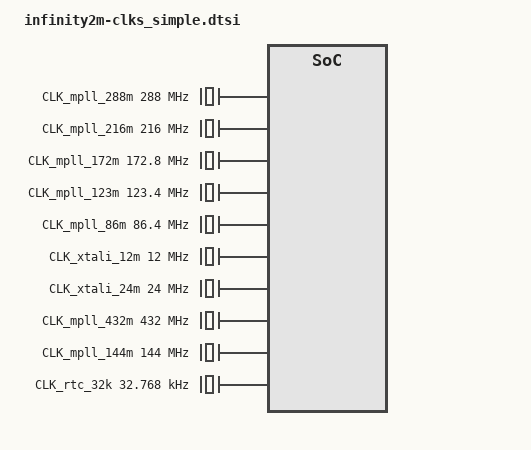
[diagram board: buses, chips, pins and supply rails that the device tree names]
/*
* infinity2m-clks_simple.dtsi- Sigmastar
*
* Copyright (c) [2019~2020] SigmaStar Technology.
*
*
* This software is licensed under the terms of the GNU General Public
* License version 2, as published by the Free Software Foundation, and
* may be copied, distributed, and modified under those terms.
*
* This program is distributed in the hope that it will be useful,
* but WITHOUT ANY WARRANTY; without even the implied warranty of
* MERCHANTABILITY or FITNESS FOR A PARTICULAR PURPOSE.  See the
* GNU General Public License version 2 for more details.
*
*/
/* generated manually for fast booting */

CLK_VOID: CLK_VOID {
    #clock-cells = <0>;
    compatible = "fixed-clock";
    clock-frequency = <1>;
};
 
CLK_upll_384m: CLK_upll_384m {
    #clock-cells = <0>;
    compatible = "fixed-factor-clock";
    clocks = <&CLK_upll>;
    clock-div = <5>;
    clock-mult = <4>;
};
 
CLK_upll_320m: CLK_upll_320m {
    #clock-cells = <0>;
    compatible = "fixed-factor-clock";
    clocks = <&CLK_upll>;
    clock-div = <3>;
    clock-mult = <2>;
};
 
CLK_mpll_288m: CLK_mpll_288m {
    #clock-cells = <0>;
    compatible = "fixed-clock";
    clock-frequency = <288000000>;
};
 
CLK_utmi_240m: CLK_utmi_240m {
    #clock-cells = <0>;
    compatible = "fixed-factor-clock";
    clocks = <&CLK_utmi>;
    clock-div = <2>;
    clock-mult = <1>;
};
 
CLK_mpll_216m: CLK_mpll_216m {
    #clock-cells = <0>;
    compatible = "fixed-clock";
    clock-frequency = <216000000>;
};
 
CLK_utmi_192m: CLK_utmi_192m {
    #clock-cells = <0>;
    compatible = "fixed-factor-clock";
    clocks = <&CLK_utmi>;
    clock-div = <5>;
    clock-mult = <2>;
};
 
CLK_mpll_172m: CLK_mpll_172m {
    #clock-cells = <0>;
    compatible = "fixed-clock";
    clock-frequency = <172800000>;
};
 
CLK_utmi_160m: CLK_utmi_160m {
    #clock-cells = <0>;
    compatible = "fixed-factor-clock";
    clocks = <&CLK_utmi>;
    clock-div = <3>;
    clock-mult = <1>;
};
 
CLK_mpll_123m: CLK_mpll_123m {
    #clock-cells = <0>;
    compatible = "fixed-clock";
    clock-frequency = <123400000>;
};
 
CLK_mpll_86m: CLK_mpll_86m {
    #clock-cells = <0>;
    compatible = "fixed-clock";
    clock-frequency = <86400000>;
};
 
CLK_mpll_288m_div2: CLK_mpll_288m_div2 {
    #clock-cells = <0>;
    compatible = "fixed-factor-clock";
    clocks = <&CLK_mpll_288m>;
    clock-div = <2>;
    clock-mult = <1>;
};
 
CLK_mpll_288m_div4: CLK_mpll_288m_div4 {
    #clock-cells = <0>;
    compatible = "fixed-factor-clock";
    clocks = <&CLK_mpll_288m>;
    clock-div = <4>;
    clock-mult = <1>;
};
 
CLK_mpll_288m_div8: CLK_mpll_288m_div8 {
    #clock-cells = <0>;
    compatible = "fixed-factor-clock";
    clocks = <&CLK_mpll_288m>;
    clock-div = <8>;
    clock-mult = <1>;
};
CLK_mpll_216m_div2: CLK_mpll_216m_div2 {
    #clock-cells = <0>;
    compatible = "fixed-factor-clock";
    clocks = <&CLK_mpll_216m>;
    clock-div = <2>;
    clock-mult = <1>;
};
 
CLK_mpll_216m_div4: CLK_mpll_216m_div4 {
    #clock-cells = <0>;
    compatible = "fixed-factor-clock";
    clocks = <&CLK_mpll_216m>;
    clock-div = <4>;
    clock-mult = <1>;
};
 
CLK_mpll_216m_div8: CLK_mpll_216m_div8 {
    #clock-cells = <0>;
    compatible = "fixed-factor-clock";
    clocks = <&CLK_mpll_216m>;
    clock-div = <8>;
    clock-mult = <1>;
};
CLK_mpll_86m_div2: CLK_mpll_86m_div2 {
    #clock-cells = <0>;
    compatible = "fixed-factor-clock";
    clocks = <&CLK_mpll_86m>;
    clock-div = <2>;
    clock-mult = <1>;
};
CLK_utmi_192m_div4: CLK_utmi_192m_div4 {
    #clock-cells = <0>;
    compatible = "fixed-factor-clock";
    clocks = <&CLK_utmi_192m>;
    clock-div = <4>;
    clock-mult = <1>;
};
 
CLK_utmi_160m_div4: CLK_utmi_160m_div4 {
    #clock-cells = <0>;
    compatible = "fixed-factor-clock";
    clocks = <&CLK_utmi_160m>;
    clock-div = <4>;
    clock-mult = <1>;
};
 
CLK_utmi_160m_div5: CLK_utmi_160m_div5 {
    #clock-cells = <0>;
    compatible = "fixed-factor-clock";
    clocks = <&CLK_utmi_160m>;
    clock-div = <5>;
    clock-mult = <1>;
};
 
CLK_utmi_160m_div8: CLK_utmi_160m_div8 {
    #clock-cells = <0>;
    compatible = "fixed-factor-clock";
    clocks = <&CLK_utmi_160m>;
    clock-div = <8>;
    clock-mult = <1>;
};
 
CLK_xtali_12m: CLK_xtali_12m {
    #clock-cells = <0>;
    compatible = "fixed-clock";
    clock-frequency = <12000000>;
};
 
CLK_xtali_12m_div8: CLK_xtali_12m_div8 {
    #clock-cells = <0>;
    compatible = "fixed-factor-clock";
    clocks = <&CLK_xtali_12m>;
    clock-div = <8>;
    clock-mult = <1>;
};
 
CLK_xtali_12m_div16: CLK_xtali_12m_div16 {
    #clock-cells = <0>;
    compatible = "fixed-factor-clock";
    clocks = <&CLK_xtali_12m>;
    clock-div = <16>;
    clock-mult = <1>;
};
 
CLK_xtali_12m_div40: CLK_xtali_12m_div40 {
    #clock-cells = <0>;
    compatible = "fixed-factor-clock";
    clocks = <&CLK_xtali_12m>;
    clock-div = <40>;
    clock-mult = <1>;
};
CLK_xtali_24m: CLK_xtali_24m {
    #clock-cells = <0>;
    compatible = "fixed-clock";
    clock-frequency = <24000000>;
};
CLK_miu_p: CLK_miu_p {
    #clock-cells = <0>;
    compatible = "fixed-factor-clock";
    clocks = <&CLK_miu>;
    clock-div = <1>;
    clock-mult = <1>;
};
 
CLK_mspi0_p: CLK_mspi0_p {
    #clock-cells = <0>;
    compatible = "fixed-factor-clock";
    clocks = <&CLK_mspi0>;
    clock-div = <1>;
    clock-mult = <1>;
};
 
CLK_mspi1_p: CLK_mspi1_p {
    #clock-cells = <0>;
    compatible = "fixed-factor-clock";
    clocks = <&CLK_mspi1>;
    clock-div = <1>;
    clock-mult = <1>;
};
 
CLK_miu_sc_gp_p: CLK_miu_sc_gp_p {
    #clock-cells = <0>;
    compatible = "fixed-factor-clock";
    clocks = <&CLK_miu_sc_gp>;
    clock-div = <1>;
    clock-mult = <1>;
};
 
CLK_miu2x_p: CLK_miu2x_p {
    #clock-cells = <0>;
    compatible = "fixed-factor-clock";
    clocks = <&CLK_miu2x>;
    clock-div = <1>;
    clock-mult = <1>;
};
 
CLK_mcu_p: CLK_mcu_p {
    #clock-cells = <0>;
    compatible = "fixed-factor-clock";
    clocks = <&CLK_mcu>;
    clock-div = <1>;
    clock-mult = <1>;
};
 
CLK_mcu_pm_p: CLK_mcu_pm_p {
    #clock-cells = <0>;
    compatible = "fixed-factor-clock";
    clocks = <&CLK_mcu>;
    clock-div = <1>;
    clock-mult = <1>;
};
 
CLK_sdio_p: CLK_sdio_p {
    #clock-cells = <0>;
    compatible = "fixed-factor-clock";
    clocks = <&CLK_sdio>;
    clock-div = <1>;
    clock-mult = <1>;
};
 
CLK_fcie_p: CLK_fcie_p {
    #clock-cells = <0>;
    compatible = "fixed-clock";
    clock-frequency = <1>;
};
 
 
CLK_eth_buf: CLK_eth_buf {
    #clock-cells = <0>;
    compatible = "fixed-clock";
    clock-frequency = <1>;
};
 
CLK_rmii_buf: CLK_rmii_buf {
    #clock-cells = <0>;
    compatible = "fixed-clock";
    clock-frequency = <1>;
};
 
CLK_emac_testrx125_in_lan: CLK_emac_testrx125_in_lan {
    #clock-cells = <0>;
    compatible = "fixed-clock";
    clock-frequency = <1>;
};
CLK_mpll_432m: CLK_mpll_432m {
    #clock-cells = <0>;
    compatible = "fixed-clock";
    clock-frequency = <432000000>;
};
 
CLK_hdmi_in: CLK_hdmi_in {
    #clock-cells = <0>;
    compatible = "fixed-clock";
    clock-frequency = <432000000>;
};
 
CLK_dac_in: CLK_dac_in {
    #clock-cells = <0>;
    compatible = "fixed-clock";
    clock-frequency = <432000000>;
};
CLK_miu_sc_gp: CLK_miu_sc_gp {
    #clock-cells = <0>;
    compatible = "fixed-factor-clock";
    clocks = <&CLK_miu_p>;
    clock-div = <1>;
    clock-mult = <1>;
};
CLK_miu2x: CLK_miu2x {
    #clock-cells = <0>;
    compatible = "fixed-factor-clock";
    clocks = <&CLK_ddrpll_clk>;
    clock-div = <1>;
    clock-mult = <1>;
};
CLK_mpll_144m: CLK_mpll_144m {
    #clock-cells = <0>;
    compatible = "fixed-clock";
    clock-frequency = <144000000>;
};
 
CLK_mpll_144m_div2: CLK_mpll_144m_div2 {
    #clock-cells = <0>;
    compatible = "fixed-factor-clock";
    clocks = <&CLK_mpll_144m>;
    clock-div = <2>;
    clock-mult = <1>;
};
 
CLK_mpll_144m_div4: CLK_mpll_144m_div4 {
    #clock-cells = <0>;
    compatible = "fixed-factor-clock";
    clocks = <&CLK_mpll_144m>;
    clock-div = <4>;
    clock-mult = <1>;
};
 
CLK_xtali_12m_div2: CLK_xtali_12m_div2 {
    #clock-cells = <0>;
    compatible = "fixed-factor-clock";
    clocks = <&CLK_xtali_12m>;
    clock-div = <2>;
    clock-mult = <1>;
};
 
CLK_xtali_12m_div4: CLK_xtali_12m_div4 {
    #clock-cells = <0>;
    compatible = "fixed-factor-clock";
    clocks = <&CLK_xtali_12m>;
    clock-div = <4>;
    clock-mult = <1>;
};
 
CLK_xtali_12m_div12: CLK_xtali_12m_div12 {
    #clock-cells = <0>;
    compatible = "fixed-factor-clock";
    clocks = <&CLK_xtali_12m>;
    clock-div = <12>;
    clock-mult = <1>;
};
CLK_rtc_32k: CLK_rtc_32k {
    #clock-cells = <0>;
    compatible = "fixed-clock";
    clock-frequency = <32768>;
};
 
CLK_rtc_32k_div4: CLK_rtc_32k_div4 {
    #clock-cells = <0>;
    compatible = "fixed-factor-clock";
    clocks = <&CLK_rtc_32k>;
    clock-div = <4>;
    clock-mult = <1>;
};
 
 
CLK_miupll_clk: CLK_miupll_clk {
    #clock-cells = <0>;
    compatible = "sstar,complex-clock";
    clocks = <&CLK_xtali_24m>;
};
 
CLK_ddrpll_clk: CLK_ddrpll_clk {
    #clock-cells = <0>;
    compatible = "sstar,complex-clock";
    clocks = <&CLK_ddr_syn>;
};
CLK_cpupll_clk: CLK_cpupll_clk {
    #clock-cells = <0>;
    compatible = "sstar,complex-clock";
    clocks = <&CLK_mpll_432m>;
};
CLK_utmi: CLK_utmi {
    #clock-cells = <0>;
    compatible = "fixed-clock";
    clock-frequency = <480000000>;
};

CLK_upll: CLK_upll {
    #clock-cells = <0>;
    compatible = "fixed-clock";
    clock-frequency = <480000000>;
};

CLK_fuart0_synth_out: CLK_fuart0_synth_out {
    #clock-cells = <0>;
    compatible = "sstar,complex-clock";
    clocks = <&CLK_fuart0_synth_in>;
};
 
CLK_miu: CLK_miu {
    #clock-cells = <0>;
    compatible = "sstar,composite-clock";
    clocks = <&CLK_ddrpll_clk>,<&CLK_VOID>,<&CLK_miupll_clk>,<&CLK_mpll_216m>;
    reg = <REG_CKG_MIU_BASE 0x4>;
    mux-shift = <2>;  //2+REG_CKG_MIU_OFFSET
    mux-width = <2>;
    gate-shift = <0>;  //0+REG_CKG_MIU_OFFSET
    glitch-shift = <4>;  //4+REG_CKG_MIU_OFFSET
    auto-enable = <1>;
};
CLK_bdma: CLK_bdma {
    #clock-cells = <0>;
    compatible = "sstar,composite-clock";
    clocks = <&CLK_miu_p>,<&CLK_VOID>,<&CLK_VOID>,<&CLK_VOID>;
    reg = <REG_CKG_BDMA_BASE 0x4>;
    mux-shift = <2>;  //2+REG_CKG_BDMA_OFFSET
    mux-width = <2>;
    gate-shift = <0>;  //0+REG_CKG_BDMA_OFFSET
};
 
CLK_ddr_syn: CLK_ddr_syn {
    #clock-cells = <0>;
    compatible = "sstar,composite-clock";
    clocks = <&CLK_mpll_432m>,<&CLK_mpll_216m>,<&CLK_xtali_12m>,<&CLK_VOID>;
    reg = <REG_CKG_DDR_SYN_BASE 0x4>;
    mux-shift = <2>;  //2+REG_CKG_DDR_SYN_OFFSET
    mux-width = <2>;
    gate-shift = <0>;  //0+REG_CKG_DDR_SYN_OFFSET
    auto-enable = <1>;
};
CLK_mcu: CLK_mcu {
    #clock-cells = <0>;
    compatible = "sstar,composite-clock";
    clocks = <&CLK_mpll_216m>,<&CLK_mpll_172m>,<&CLK_mpll_288m_div2>,<&CLK_mpll_216m_div4>,<&CLK_mpll_432m>,<&CLK_upll_384m>,<&CLK_upll_320m>,<&CLK_mpll_216m_div2>;
    reg = <REG_CKG_MCU_BASE 0x4>;
    mux-shift = <2>;  //2+REG_CKG_MCU_OFFSET
    mux-width = <3>;
    gate-shift = <0>;  //0+REG_CKG_MCU_OFFSET
    glitch-shift = <5>;  //5+REG_CKG_MCU_OFFSET
    auto-enable = <1>;
};
 
CLK_riubrdg: CLK_riubrdg {
    #clock-cells = <0>;
    compatible = "sstar,composite-clock";
    clocks = <&CLK_mcu_p>,<&CLK_VOID>,<&CLK_VOID>,<&CLK_VOID>;
    reg = <REG_CKG_RIUBRDG_BASE 0x4>;
    mux-shift = <10>;  //2+REG_CKG_RIUBRDG_OFFSET
    mux-width = <2>;
    gate-shift = <8>;  //0+REG_CKG_RIUBRDG_OFFSET
    auto-enable = <1>;
};
 
CLK_spi: CLK_spi {
    #clock-cells = <0>;
    compatible = "sstar,composite-clock";
    clocks = <&CLK_mpll_216m>,<&CLK_mpll_216m_div2>,<&CLK_mpll_86m>,<&CLK_mpll_288m_div4>,<&CLK_miu_p>,<&CLK_VOID>,<&CLK_VOID>,<&CLK_VOID>;
    reg = <REG_CKG_SPI_BASE 0x4>;
    mux-shift = <10>;  //2+REG_CKG_SPI_OFFSET
    mux-width = <3>;
    gate-shift = <8>;  //0+REG_CKG_SPI_OFFSET
    auto-enable = <1>;
};
 
CLK_uart0: CLK_uart0 {
    #clock-cells = <0>;
    compatible = "sstar,composite-clock";
    clocks = <&CLK_mpll_172m>,<&CLK_mpll_288m_div2>,<&CLK_xtali_12m>,<&CLK_VOID>;
    reg = <REG_CKG_UART0_BASE 0x4>;
    mux-shift = <2>;  //2+REG_CKG_UART0_OFFSET
    mux-width = <2>;
    gate-shift = <0>;  //0+REG_CKG_UART0_OFFSET
};
 
CLK_uart1: CLK_uart1 {
    #clock-cells = <0>;
    compatible = "sstar,composite-clock";
    clocks = <&CLK_mpll_172m>,<&CLK_mpll_288m_div2>,<&CLK_xtali_12m>,<&CLK_VOID>;
    reg = <REG_CKG_UART1_BASE 0x4>;
    mux-shift = <10>;  //2+REG_CKG_UART1_OFFSET
    mux-width = <2>;
    gate-shift = <8>;  //0+REG_CKG_UART1_OFFSET
};
 
CLK_uart2: CLK_uart2 {
    #clock-cells = <0>;
    compatible = "sstar,composite-clock";
    clocks = <&CLK_mpll_172m>,<&CLK_mpll_288m_div2>,<&CLK_xtali_12m>,<&CLK_VOID>;
    reg = <REG_CKG_UART2_BASE 0x4>;
    mux-shift = <14>;  //2+REG_CKG_UART2_OFFSET
    mux-width = <2>;
    gate-shift = <12>;  //0+REG_CKG_UART2_OFFSET
};
 
CLK_fuart0_synth_in: CLK_fuart0_synth_in {
    #clock-cells = <0>;
    compatible = "sstar,composite-clock";
    clocks = <&CLK_mpll_432m>,<&CLK_mpll_216m>,<&CLK_VOID>,<&CLK_VOID>;
    reg = <REG_CKG_FUART0_SYNTH_IN_BASE 0x4>;
    mux-shift = <6>;  //2+REG_CKG_FUART0_SYNTH_IN_OFFSET
    mux-width = <2>;
    gate-shift = <4>;  //0+REG_CKG_FUART0_SYNTH_IN_OFFSET
};
 
CLK_fuart: CLK_fuart {
    #clock-cells = <0>;
    compatible = "sstar,composite-clock";
    clocks = <&CLK_mpll_172m>,<&CLK_mpll_288m_div2>,<&CLK_xtali_12m>,<&CLK_fuart0_synth_out>;
    reg = <REG_CKG_FUART_BASE 0x4>;
    mux-shift = <2>;  //2+REG_CKG_FUART_OFFSET
    mux-width = <2>;
    gate-shift = <0>;  //0+REG_CKG_FUART_OFFSET
};
 
CLK_mspi0: CLK_mspi0 {
    #clock-cells = <0>;
    compatible = "sstar,composite-clock";
    clocks = <&CLK_mpll_216m_div2>,<&CLK_mpll_216m_div4>,<&CLK_xtali_12m>,<&CLK_mpll_288m_div2>;
    reg = <REG_CKG_MSPI0_BASE 0x4>;
    mux-shift = <2>;  //2+REG_CKG_MSPI0_OFFSET
    mux-width = <2>;
    gate-shift = <0>;  //0+REG_CKG_MSPI0_OFFSET
};
 
CLK_mspi1: CLK_mspi1 {
    #clock-cells = <0>;
    compatible = "sstar,composite-clock";
    clocks = <&CLK_mpll_216m_div2>,<&CLK_mpll_216m_div4>,<&CLK_xtali_12m>,<&CLK_mpll_288m_div2>;
    reg = <REG_CKG_MSPI1_BASE 0x4>;
    mux-shift = <10>;  //2+REG_CKG_MSPI1_OFFSET
    mux-width = <2>;
    gate-shift = <8>;  //0+REG_CKG_MSPI1_OFFSET
};
 
CLK_mspi: CLK_mspi {
    #clock-cells = <0>;
    compatible = "sstar,composite-clock";
    clocks = <&CLK_mspi0_p>,<&CLK_mspi1_p>;
    reg = <REG_CKG_MSPI_BASE 0x4>;
    mux-shift = <14>;  //2+REG_CKG_MSPI_OFFSET
    mux-width = <1>;
    gate-shift = <12>;  //0+REG_CKG_MSPI_OFFSET
};
 
CLK_miic0: CLK_miic0 {
    #clock-cells = <0>;
    compatible = "sstar,composite-clock";
    clocks = <&CLK_mpll_288m_div4>,<&CLK_mpll_216m_div4>,<&CLK_xtali_12m>,<&CLK_VOID>;
    reg = <REG_CKG_MIIC0_BASE 0x4>;
    mux-shift = <2>;  //2+REG_CKG_MIIC0_OFFSET
    mux-width = <2>;
    gate-shift = <0>;  //0+REG_CKG_MIIC0_OFFSET
};
 
CLK_miic1: CLK_miic1 {
    #clock-cells = <0>;
    compatible = "sstar,composite-clock";
    clocks = <&CLK_mpll_288m_div4>,<&CLK_mpll_216m_div4>,<&CLK_xtali_12m>,<&CLK_VOID>;
    reg = <REG_CKG_MIIC1_BASE 0x4>;
    mux-shift = <10>;  //2+REG_CKG_MIIC1_OFFSET
    mux-width = <2>;
    gate-shift = <8>;  //0+REG_CKG_MIIC1_OFFSET
};
 
CLK_sata_phy_108: CLK_sata_phy_108 {
    #clock-cells = <0>;
    compatible = "sstar,composite-clock";
    clocks = <&CLK_mpll_216m_div2>,<&CLK_VOID>,<&CLK_VOID>,<&CLK_VOID>;
    reg = <REG_CKG_SATA_PHY_108_BASE 0x4>;
    mux-shift = <2>;  //2+REG_CKG_SATA_PHY_108_OFFSET
    mux-width = <2>;
    gate-shift = <0>;  //0+REG_CKG_SATA_PHY_108_OFFSET
};
 
CLK_sata_phy_432: CLK_sata_phy_432 {
    #clock-cells = <0>;
    compatible = "sstar,composite-clock";
    clocks = <&CLK_mpll_432m>,<&CLK_VOID>,<&CLK_VOID>,<&CLK_VOID>;
    reg = <REG_CKG_SATA_PHY_432_BASE 0x4>;
    mux-shift = <10>;  //2+REG_CKG_SATA_PHY_432_OFFSET
    mux-width = <2>;
    gate-shift = <8>;  //0+REG_CKG_SATA_PHY_432_OFFSET
};
CLK_emac_ahb: CLK_emac_ahb {
    #clock-cells = <0>;
    compatible = "sstar,composite-clock";
    clocks = <&CLK_mpll_288m_div2>,<&CLK_mpll_123m>,<&CLK_mpll_86m>,<&CLK_emac_testrx125_in_lan>;
    reg = <REG_CKG_EMAC_AHB_BASE 0x4>;
    mux-shift = <2>;  //2+REG_CKG_EMAC_AHB_OFFSET
    mux-width = <2>;
    gate-shift = <0>;  //0+REG_CKG_EMAC_AHB_OFFSET
};
 
CLK_jpe: CLK_jpe {
    #clock-cells = <0>;
    compatible = "sstar,composite-clock";
    clocks = <&CLK_VOID>,<&CLK_VOID>,<&CLK_VOID>,<&CLK_upll_320m>,<&CLK_mpll_288m>,<&CLK_mpll_216m>,<&CLK_VOID>,<&CLK_VOID>; //max safe clock is 320m
    reg = <REG_CKG_JPE_BASE 0x4>;
    mux-shift = <2>;  //2+REG_CKG_JPE_OFFSET
    mux-width = <3>;
    gate-shift = <0>;  //0+REG_CKG_JPE_OFFSET
};
 
CLK_aesdma: CLK_aesdma {
    #clock-cells = <0>;
    compatible = "sstar,composite-clock";
    clocks = <&CLK_mpll_86m>,<&CLK_mpll_172m>,<&CLK_VOID>,<&CLK_VOID>;
    reg = <REG_CKG_AESDMA_BASE 0x4>;
    mux-shift = <2>;  //2+REG_CKG_AESDMA_OFFSET
    mux-width = <2>;
    gate-shift = <0>;  //0+REG_CKG_AESDMA_OFFSET
    glitch-shift = <4>;  //4+REG_CKG_AESDMA_OFFSET
};
CLK_sdio: CLK_sdio {
    #clock-cells = <0>;
    compatible = "sstar,composite-clock";
    clocks = <&CLK_utmi_192m_div4>,<&CLK_mpll_86m_div2>,<&CLK_utmi_160m_div4>,<&CLK_mpll_288m_div8>,<&CLK_utmi_160m_div5>,<&CLK_utmi_160m_div8>,<&CLK_xtali_12m>,<&CLK_xtali_12m_div40>;
    reg = <REG_CKG_SDIO_BASE 0x4>;
    mux-shift = <2>;  //2+REG_CKG_SDIO_OFFSET
    mux-width = <3>;
    gate-shift = <0>;  //0+REG_CKG_SDIO_OFFSET
};
CLK_sata_pm: CLK_sata_pm {
    #clock-cells = <0>;
    compatible = "sstar,composite-clock";
    clocks = <&CLK_mpll_216m_div2>,<&CLK_xtali_12m>,<&CLK_xtali_24m>,<&CLK_mpll_123m>;
    reg = <REG_CKG_SATA_PM_BASE 0x4>;
    mux-shift = <10>;  //2+REG_CKG_SATA_PM_OFFSET
    mux-width = <2>;
    gate-shift = <8>;  //0+REG_CKG_SATA_PM_OFFSET
};
 
CLK_sata_axi: CLK_sata_axi {
    #clock-cells = <0>;
    compatible = "sstar,composite-clock";
    clocks = <&CLK_utmi_240m>,<&CLK_mpll_288m>,<&CLK_VOID>,<&CLK_VOID>;
    reg = <REG_CKG_SATA_AXI_BASE 0x4>;
    mux-shift = <2>;  //2+REG_CKG_SATA_AXI_OFFSET
    mux-width = <2>;
    gate-shift = <0>;  //0+REG_CKG_SATA_AXI_OFFSET
};
CLK_dac: CLK_dac {
    #clock-cells = <0>;
    compatible = "sstar,composite-clock";
    clocks = <&CLK_dac_in>,<&CLK_hdmi_in>,<&CLK_VOID>,<&CLK_VOID>;
    reg = <REG_CKG_DAC_BASE 0x4>;
    mux-shift = <2>;  //2+REG_CKG_DAC_OFFSET
    mux-width = <2>;
    gate-shift = <0>;  //0+REG_CKG_DAC_OFFSET
};
 
CLK_emac1_tx: CLK_emac1_tx {
    #clock-cells = <0>;
    compatible = "sstar,composite-clock";
    clocks = <&CLK_eth_buf>,<&CLK_rmii_buf>;
    reg = <REG_CKG_EMAC1_TX_BASE 0x4>;
    mux-shift = <2>;  //2+REG_CKG_EMAC1_TX_OFFSET
    mux-width = <1>;
    gate-shift = <0>;  //0+REG_CKG_EMAC1_TX_OFFSET
};
 
CLK_emac1_rx: CLK_emac1_rx {
    #clock-cells = <0>;
    compatible = "sstar,composite-clock";
    clocks = <&CLK_eth_buf>,<&CLK_rmii_buf>;
    reg = <REG_CKG_EMAC1_RX_BASE 0x4>;
    mux-shift = <2>;  //2+REG_CKG_EMAC1_RX_OFFSET
    mux-width = <1>;
    gate-shift = <0>;  //0+REG_CKG_EMAC1_RX_OFFSET
};
 
CLK_emac1_tx_ref: CLK_emac1_tx_ref {
    #clock-cells = <0>;
    compatible = "sstar,composite-clock";
    clocks = <&CLK_rmii_buf>,<&CLK_VOID>;
    reg = <REG_CKG_EMAC1_TX_REF_BASE 0x4>;
    mux-shift = <10>;  //2+REG_CKG_EMAC1_TX_REF_OFFSET
    mux-width = <1>;
    gate-shift = <8>;  //0+REG_CKG_EMAC1_TX_REF_OFFSET
};
 
CLK_emac1_rx_ref: CLK_emac1_rx_ref {
    #clock-cells = <0>;
    compatible = "sstar,composite-clock";
    clocks = <&CLK_rmii_buf>,<&CLK_VOID>;
    reg = <REG_CKG_EMAC1_RX_REF_BASE 0x4>;
    mux-shift = <10>;  //2+REG_CKG_EMAC1_RX_REF_OFFSET
    mux-width = <1>;
    gate-shift = <8>;  //0+REG_CKG_EMAC1_RX_REF_OFFSET
};
 
CLK_emac_tx: CLK_emac_tx {
    #clock-cells = <0>;
    compatible = "sstar,composite-clock";
    clocks = <&CLK_eth_buf>,<&CLK_rmii_buf>;
    reg = <REG_CKG_EMAC_TX_BASE 0x4>;
    mux-shift = <2>;  //2+REG_CKG_EMAC_TX_OFFSET
    mux-width = <1>;
    gate-shift = <0>;  //0+REG_CKG_EMAC_TX_OFFSET
};
 
CLK_emac_rx: CLK_emac_rx {
    #clock-cells = <0>;
    compatible = "sstar,composite-clock";
    clocks = <&CLK_eth_buf>,<&CLK_rmii_buf>;
    reg = <REG_CKG_EMAC_RX_BASE 0x4>;
    mux-shift = <2>;  //2+REG_CKG_EMAC_RX_OFFSET
    mux-width = <1>;
    gate-shift = <0>;  //0+REG_CKG_EMAC_RX_OFFSET
};
 
CLK_emac_tx_ref: CLK_emac_tx_ref {
    #clock-cells = <0>;
    compatible = "sstar,composite-clock";
    clocks = <&CLK_rmii_buf>,<&CLK_VOID>;
    reg = <REG_CKG_EMAC_TX_REF_BASE 0x4>;
    mux-shift = <10>;  //2+REG_CKG_EMAC_TX_REF_OFFSET
    mux-width = <1>;
    gate-shift = <8>;  //0+REG_CKG_EMAC_TX_REF_OFFSET
};
 
CLK_emac_rx_ref: CLK_emac_rx_ref {
    #clock-cells = <0>;
    compatible = "sstar,composite-clock";
    clocks = <&CLK_rmii_buf>,<&CLK_VOID>;
    reg = <REG_CKG_EMAC_RX_REF_BASE 0x4>;
    mux-shift = <10>;  //2+REG_CKG_EMAC_RX_REF_OFFSET
    mux-width = <1>;
    gate-shift = <8>;  //0+REG_CKG_EMAC_RX_REF_OFFSET
};
 
CLK_hemcu_216m: CLK_hemcu_216m {
    #clock-cells = <0>;
    compatible = "sstar,composite-clock";
    clocks = <&CLK_mpll_216m>;
    reg = <REG_CKG_HEMCU_216M_BASE 0x4>;
    gate-shift = <0>;  //0+REG_CKG_HEMCU_216M_OFFSET
    auto-enable = <1>;
};
 
CLK_spi_pm: CLK_spi_pm {
    #clock-cells = <0>;
    compatible = "sstar,composite-clock";
    clocks = <&CLK_rtc_32k>,<&CLK_mpll_216m_div8>,<&CLK_mpll_144m_div4>,<&CLK_mpll_86m_div2>,<&CLK_mpll_216m_div4>,<&CLK_mpll_144m_div2>,<&CLK_mpll_86m>,<&CLK_mpll_216m_div2>,<&CLK_xtali_12m_div8>,<&CLK_xtali_12m_div12>,<&CLK_rtc_32k_div4>,<&CLK_xtali_12m_div16>,<&CLK_xtali_12m_div2>,<&CLK_xtali_12m_div4>,<&CLK_xtali_12m>,<&CLK_xtali_24m>;
    reg = <REG_CKG_SPI_BASE 0x4>;
    mux-shift = <10>;  //2+REG_CKG_SPI_OFFSET
    mux-width = <4>;
    gate-shift = <8>;  //0+REG_CKG_SPI_OFFSET
    glitch-shift = <14>;  //6+REG_CKG_SPI_OFFSET
    auto-enable = <1>;
};
 
CLK_pm_sleep: CLK_pm_sleep {
    #clock-cells = <0>;
    compatible = "sstar,composite-clock";
    clocks = <&CLK_xtali_12m>,<&CLK_rtc_32k>,<&CLK_xtali_12m_div8>,<&CLK_xtali_12m_div12>,<&CLK_rtc_32k_div4>,<&CLK_xtali_12m_div16>,<&CLK_xtali_12m_div2>,<&CLK_xtali_12m_div4>;
    reg = <REG_CKG_PM_SLEEP_BASE 0x4>;
    mux-shift = <12>;  //2+REG_CKG_PM_SLEEP_OFFSET
    mux-width = <3>;
    auto-enable = <1>;
};
 
CLK_pwm: CLK_pwm {
    #clock-cells = <0>;
    compatible = "sstar,composite-clock";
    clocks = <&CLK_xtali_12m>,<&CLK_rtc_32k>,<&CLK_xtali_12m_div8>,<&CLK_xtali_12m_div12>,<&CLK_rtc_32k_div4>,<&CLK_mpll_86m>,<&CLK_xtali_12m_div2>,<&CLK_xtali_12m_div4>;
    reg = <REG_CKG_PWM_BASE 0x4>;
    mux-shift = <12>;  //2+REG_CKG_PWM_OFFSET
    mux-width = <3>;
};
 
CLK_sar: CLK_sar {
    #clock-cells = <0>;
    compatible = "sstar,composite-clock";
    clocks = <&CLK_xtali_12m>,<&CLK_rtc_32k>,<&CLK_xtali_12m_div8>,<&CLK_xtali_12m_div12>,<&CLK_rtc_32k_div4>,<&CLK_xtali_12m_div16>,<&CLK_xtali_12m_div2>,<&CLK_xtali_12m_div4>;
    reg = <REG_CKG_SAR_BASE 0x4>;
    mux-shift = <7>;  //2+REG_CKG_SAR_OFFSET
    mux-width = <3>;
    gate-shift = <5>;  //0+REG_CKG_SAR_OFFSET
};
 
CLK_rtc: CLK_rtc {
    #clock-cells = <0>;
    compatible = "sstar,composite-clock";
    clocks = <&CLK_xtali_12m>,<&CLK_rtc_32k>,<&CLK_VOID>,<&CLK_VOID>;
    reg = <REG_CKG_RTC_BASE 0x4>;
    mux-shift = <2>;  //2+REG_CKG_RTC_OFFSET
    mux-width = <2>;
    gate-shift = <0>;  //0+REG_CKG_RTC_OFFSET
};
 
CLK_ir: CLK_ir {
    #clock-cells = <0>;
    compatible = "sstar,composite-clock";
    clocks = <&CLK_xtali_12m>,<&CLK_rtc_32k>,<&CLK_xtali_12m_div8>,<&CLK_xtali_12m_div12>,<&CLK_rtc_32k_div4>,<&CLK_xtali_12m_div16>,<&CLK_xtali_12m_div2>,<&CLK_xtali_12m_div4>;
    reg = <REG_CKG_IR_BASE 0x4>;
    mux-shift = <7>;  //2+REG_CKG_IR_OFFSET
    mux-width = <3>;
    gate-shift = <5>;  //0+REG_CKG_IR_OFFSET
};
#ifdef CONFIG_MS_USCLK
usclk: usclk {
    compatible = "usclk";
    clocks = <&CLK_RTC_CLK_32K>, <&CLK_VOID>, <&CLK_aesdma>, <&CLK_armpll_37p125m>, <&CLK_axi2x>, <&CLK_bdma>, <&CLK_bist>, <&CLK_bist_dec_gp>, <&CLK_bist_sc_gp>, <&CLK_ccir_in_clk>, <&CLK_cpupll_clk>, <&CLK_csi2_mac_p>, <&CLK_dac>, <&CLK_dac_in>, <&CLK_ddr_syn>, <&CLK_ddrpll_clk>, <&CLK_dec_aclk>, <&CLK_dec_bclk>, <&CLK_dec_cclk>, <&CLK_dec_pclk>, <&CLK_dip>, <&CLK_disp_216>, <&CLK_disp_432>, <&CLK_emac1_rx>, <&CLK_emac1_rx_ref>, <&CLK_emac1_tx>, <&CLK_emac1_tx_ref>, <&CLK_emac_ahb>, <&CLK_emac_rx>, <&CLK_emac_rx_ref>, <&CLK_emac_testrx125_in_lan>, <&CLK_emac_tx>, <&CLK_emac_tx_ref>, <&CLK_eth_buf>, <&CLK_fcie_p>, <&CLK_fuart>, <&CLK_fuart0_synth_in>, <&CLK_fuart0_synth_out>, <&CLK_ge>, <&CLK_hdmi>, <&CLK_hdmi_in>, <&CLK_hemcu_216m>, <&CLK_ir>, <&CLK_jpe>, <&CLK_live>, <&CLK_live_c>, <&CLK_live_pm>, <&CLK_lpll_clk>, <&CLK_lpll_clk_div2>, <&CLK_lpll_clk_div4>, <&CLK_lpll_clk_div8>, <&CLK_mcu>, <&CLK_mcu_p>, <&CLK_mcu_pm>, <&CLK_mcu_pm_p>, <&CLK_miic0>, <&CLK_miic1>, <&CLK_mipi_tx_dsi>, <&CLK_mipi_tx_dsi_apb>, <&CLK_mipi_tx_dsi_p>, <&CLK_miu>, <&CLK_miu2x>, <&CLK_miu2x_p>, <&CLK_miu_dec_gp>, <&CLK_miu_dig>, <&CLK_miu_dma0>, <&CLK_miu_ff>, <&CLK_miu_miic0>, <&CLK_miu_miic1>, <&CLK_miu_p>, <&CLK_miu_rec>, <&CLK_miu_sc_gp>, <&CLK_miu_sc_gp_p>, <&CLK_miu_urdma>, <&CLK_miu_xd2miu>, <&CLK_miupll_clk>, <&CLK_mop>, <&CLK_mpll_123m>, <&CLK_mpll_123m_div2>, <&CLK_mpll_144m>, <&CLK_mpll_144m_div2>, <&CLK_mpll_144m_div4>, <&CLK_mpll_172m>, <&CLK_mpll_216m>, <&CLK_mpll_216m_div2>, <&CLK_mpll_216m_div4>, <&CLK_mpll_216m_div8>, <&CLK_mpll_288m>, <&CLK_mpll_288m_div2>, <&CLK_mpll_288m_div32>, <&CLK_mpll_288m_div4>, <&CLK_mpll_288m_div8>, <&CLK_mpll_432m>, <&CLK_mpll_86m>, <&CLK_mpll_86m_div16>, <&CLK_mpll_86m_div2>, <&CLK_mpll_86m_div4>, <&CLK_mspi>, <&CLK_mspi0>, <&CLK_mspi0_p>, <&CLK_mspi1>, <&CLK_mspi1_p>, <&CLK_pad2isp_sr_pclk>, <&CLK_pm_riu_w_clk_in>, <&CLK_pm_sleep>, <&CLK_pwm>, <&CLK_pwr_ctl>, <&CLK_riu>, <&CLK_riu_dec_gp>, <&CLK_riu_hemcu_gp>, <&CLK_riu_mcu_if>, <&CLK_riu_mipi_gp>, <&CLK_riu_nogating>, <&CLK_riu_pm>, <&CLK_riu_sc_gp>, <&CLK_riu_w_clk_dec_gp>, <&CLK_riu_w_clk_hemcu_gp>, <&CLK_riu_w_clk_in>, <&CLK_riu_w_clk_mcu_if_gp>, <&CLK_riu_w_clk_mipi_if_gp>, <&CLK_riu_w_clk_sc_gp>, <&CLK_riu_w_clk_top>, <&CLK_riu_w_clk_vhe_gp>, <&CLK_riubrdg>, <&CLK_rmii_buf>, <&CLK_rtc>, <&CLK_rtc_32k>, <&CLK_rtc_32k_div4>, <&CLK_sar>, <&CLK_sata_axi>, <&CLK_sata_phy_108>, <&CLK_sata_phy_432>, <&CLK_sata_pm>, <&CLK_sc_pixel>, <&CLK_sc_pixel_p>, <&CLK_sdio>, <&CLK_sdio_p>, <&CLK_spi>, <&CLK_spi_pm>, <&CLK_tck_buf>, <&CLK_uart0>, <&CLK_uart1>, <&CLK_uart2>, <&CLK_upll>, <&CLK_upll_320m>, <&CLK_upll_384m>, <&CLK_utmi>, <&CLK_utmi_160m>, <&CLK_utmi_160m_div4>, <&CLK_utmi_160m_div5>, <&CLK_utmi_160m_div8>, <&CLK_utmi_192m>, <&CLK_utmi_192m_div4>, <&CLK_utmi_240m>, <&CLK_utmi_480m>, <&CLK_xtali>, <&CLK_xtali_12m>, <&CLK_xtali_12m_div12>, <&CLK_xtali_12m_div128>, <&CLK_xtali_12m_div16>, <&CLK_xtali_12m_div2>, <&CLK_xtali_12m_div4>, <&CLK_xtali_12m_div40>, <&CLK_xtali_12m_div64>, <&CLK_xtali_12m_div8>, <&CLK_xtali_24m>, <&CLK_xtali_sc_gp>;
    clock-count = <167>;
};
#endif
